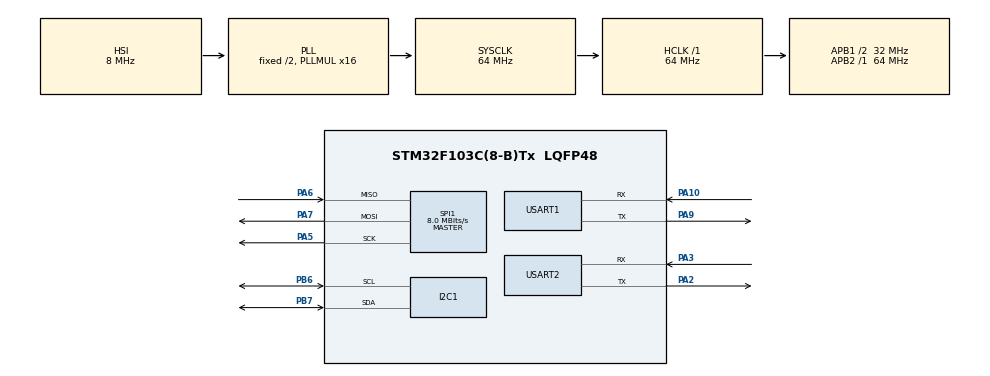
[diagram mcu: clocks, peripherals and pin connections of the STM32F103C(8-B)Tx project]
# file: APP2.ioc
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Dma.Request0=USART2_RX
Dma.Request1=USART2_TX
Dma.USART2_RX.0.Direction=DMA_PERIPH_TO_MEMORY
Dma.USART2_RX.0.Instance=DMA1_Channel6
Dma.USART2_RX.0.MemDataAlignment=DMA_MDATAALIGN_BYTE
Dma.USART2_RX.0.MemInc=DMA_MINC_ENABLE
Dma.USART2_RX.0.Mode=DMA_CIRCULAR
Dma.USART2_RX.0.PeriphDataAlignment=DMA_PDATAALIGN_BYTE
Dma.USART2_RX.0.PeriphInc=DMA_PINC_DISABLE
Dma.USART2_RX.0.Priority=DMA_PRIORITY_LOW
Dma.USART2_TX.1.Direction=DMA_MEMORY_TO_PERIPH
Dma.USART2_TX.1.Instance=DMA1_Channel7
Dma.USART2_TX.1.MemDataAlignment=DMA_MDATAALIGN_BYTE
Dma.USART2_TX.1.MemInc=DMA_MINC_ENABLE
Dma.USART2_TX.1.Mode=DMA_NORMAL
Dma.USART2_TX.1.PeriphDataAlignment=DMA_PDATAALIGN_BYTE
Dma.USART2_TX.1.PeriphInc=DMA_PINC_DISABLE
Dma.USART2_TX.1.Priority=DMA_PRIORITY_LOW
Mcu.Family=STM32F1
Mcu.Name=STM32F103C(8-B)Tx
Mcu.Package=LQFP48
NVIC.DMA1_Channel6_IRQn=true\:0\:0\:false\:false\:true\:false\:true\:true
NVIC.DMA1_Channel7_IRQn=true\:0\:0\:false\:false\:true\:false\:true\:true
NVIC.PriorityGroup=NVIC_PRIORITYGROUP_4
NVIC.USART1_IRQn=true\:0\:0\:false\:false\:true\:true\:true\:true
NVIC.USART2_IRQn=true\:0\:0\:false\:false\:true\:true\:true\:true
PA10.Mode=Asynchronous
PA10.Signal=USART1_RX
PA13.Mode=Serial_Wire
PA13.Signal=SYS_JTMS-SWDIO
PA14.Mode=Serial_Wire
PA14.Signal=SYS_JTCK-SWCLK
PA2.Mode=Asynchronous
PA2.Signal=USART2_TX
PA3.Mode=Asynchronous
PA3.Signal=USART2_RX
PA5.Mode=Full_Duplex_Master
PA5.Signal=SPI1_SCK
PA6.Mode=Full_Duplex_Master
PA6.Signal=SPI1_MISO
PA7.Mode=Full_Duplex_Master
PA7.Signal=SPI1_MOSI
PA9.Mode=Asynchronous
PA9.Signal=USART1_TX
PB6.Mode=I2C
PB6.Signal=I2C1_SCL
PB7.Mode=I2C
PB7.Signal=I2C1_SDA
PC14-OSC32_IN.Mode=LSE-External-Oscillator
PC14-OSC32_IN.Signal=RCC_OSC32_IN
PC15-OSC32_OUT.Mode=LSE-External-Oscillator
PC15-OSC32_OUT.Signal=RCC_OSC32_OUT
PD0-OSC_IN.Mode=HSE-External-Oscillator
PD0-OSC_IN.Signal=RCC_OSC_IN
PD1-OSC_OUT.Mode=HSE-External-Oscillator
PD1-OSC_OUT.Signal=RCC_OSC_OUT
ProjectManager.HeapSize=0x200
ProjectManager.StackSize=0x400
ProjectManager.TargetToolchain=MDK-ARM V5.32
RCC.AHBFreq_Value=64000000
RCC.APB1CLKDivider=RCC_HCLK_DIV2
RCC.APB1Freq_Value=32000000
RCC.APB1TimFreq_Value=64000000
RCC.APB2Freq_Value=64000000
RCC.APB2TimFreq_Value=64000000
RCC.HCLKFreq_Value=64000000
RCC.PLLMUL=RCC_PLL_MUL16
RCC.SYSCLKFreq_VALUE=64000000
RCC.SYSCLKSource=RCC_SYSCLKSOURCE_PLLCLK
RCC.USBFreq_Value=64000000
SPI1.BaudRatePrescaler=SPI_BAUDRATEPRESCALER_8
SPI1.CalculateBaudRate=8.0 MBits/s
SPI1.Direction=SPI_DIRECTION_2LINES
SPI1.Mode=SPI_MODE_MASTER
SPI1.VirtualType=VM_MASTER
USART1.VirtualMode=VM_ASYNC
USART2.VirtualMode=VM_ASYNC
VP_CRC_VS_CRC.Mode=CRC_Activate
board=custom

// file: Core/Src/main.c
/* USER CODE BEGIN Header */
/**
  ******************************************************************************
  * @file           : main.c
  * @brief          : Main program body
  ******************************************************************************
  * @attention
  *
  * Copyright (c) 2024 STMicroelectronics.
  * All rights reserved.
  *
  * This software is licensed under terms that can be found in the LICENSE file
  * in the root directory of this software component.
  * If no LICENSE file comes with this software, it is provided AS-IS.
  *
  ******************************************************************************
  */
/* USER CODE END Header */
#include "main.h"
#include "crc.h"
#include "dma.h"
#include "i2c.h"
#include "spi.h"
#include "usart.h"
#include "gpio.h"

void SystemClock_Config(void);

/* USER CODE BEGIN 0 */
int oooo;
/* USER CODE END 0 */

int main(void)
{

  /* MCU Configuration--------------------------------------------------------*/

  /* Reset of all peripherals, Initializes the Flash interface and the Systick. */
  HAL_Init();

  /* Configure the system clock */
  SystemClock_Config();

  /* Initialize all configured peripherals */
  MX_GPIO_Init();
  MX_DMA_Init();
  MX_USART1_UART_Init();
  MX_USART2_UART_Init();
  MX_CRC_Init();
  MX_I2C1_Init();
  MX_SPI1_Init();

  /* Infinite loop */
  /* USER CODE BEGIN WHILE */
  while (1)
  {
      oooo++;
      HAL_Delay(200);
    /* USER CODE END WHILE */

  }
}

void SystemClock_Config(void)
{
  RCC_OscInitTypeDef RCC_OscInitStruct = {0};
  RCC_ClkInitTypeDef RCC_ClkInitStruct = {0};

  /** Initializes the RCC Oscillators according to the specified parameters
  * in the RCC_OscInitTypeDef structure.
  */
  RCC_OscInitStruct.OscillatorType = RCC_OSCILLATORTYPE_HSI;
  RCC_OscInitStruct.HSIState = RCC_HSI_ON;
  RCC_OscInitStruct.HSICalibrationValue = RCC_HSICALIBRATION_DEFAULT;
  RCC_OscInitStruct.PLL.PLLState = RCC_PLL_ON;
  RCC_OscInitStruct.PLL.PLLSource = RCC_PLLSOURCE_HSI_DIV2;
  RCC_OscInitStruct.PLL.PLLMUL = RCC_PLL_MUL16;
  if (HAL_RCC_OscConfig(&RCC_OscInitStruct) != HAL_OK)
  {
    Error_Handler();
  }

  /** Initializes the CPU, AHB and APB buses clocks
  */
  RCC_ClkInitStruct.ClockType = RCC_CLOCKTYPE_HCLK|RCC_CLOCKTYPE_SYSCLK
                              |RCC_CLOCKTYPE_PCLK1|RCC_CLOCKTYPE_PCLK2;
  RCC_ClkInitStruct.SYSCLKSource = RCC_SYSCLKSOURCE_PLLCLK;
  RCC_ClkInitStruct.AHBCLKDivider = RCC_SYSCLK_DIV1;
  RCC_ClkInitStruct.APB1CLKDivider = RCC_HCLK_DIV2;
  RCC_ClkInitStruct.APB2CLKDivider = RCC_HCLK_DIV1;

  if (HAL_RCC_ClockConfig(&RCC_ClkInitStruct, FLASH_LATENCY_2) != HAL_OK)
  {
    Error_Handler();
  }
}

void Error_Handler(void)
{
  __disable_irq();
  while (1)
  {
  }
}
